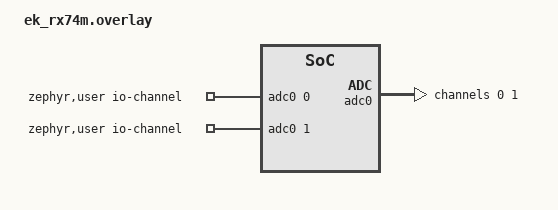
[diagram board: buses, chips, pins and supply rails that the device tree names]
/*
 * Copyright (c) 2024 Renesas Electronics Corporation
 *
 * SPDX-License-Identifier: Apache-2.0
 */

/ {
	zephyr,user {
		io-channels = <&adc0 0>, <&adc0 1>;
	};
};

&pinctrl {
	adc0_default: adc0_default {
		group1 {
			/* input */
			psels = <RX_PSEL(RX_PSEL_ADC, 4, 0)>,
				<RX_PSEL(RX_PSEL_ADC, 4, 1)>;
			renesas,analog-enable;
		};
	};
};

&adc0 {
	pinctrl-0 = <&adc0_default>;
	pinctrl-names = "default";
	status = "okay";
	#address-cells = <1>;
	#size-cells = <0>;

	channel@0 {
		reg = <0>;
		zephyr,input-positive = <RENESAS_ADC_B_CH0>;
		zephyr,gain = "ADC_GAIN_1";
		zephyr,reference = "ADC_REF_INTERNAL";
		zephyr,resolution = <16>;
		zephyr,acquisition-time = <0>;
		zephyr,vref-mv = <3300>;
	};

	channel@1 {
		reg = <1>;
		zephyr,input-positive = <RENESAS_ADC_B_CH1>;
		zephyr,gain = "ADC_GAIN_1";
		zephyr,reference = "ADC_REF_INTERNAL";
		zephyr,resolution = <16>;
		zephyr,acquisition-time = <0>;
		zephyr,vref-mv = <3300>;
	};
};
